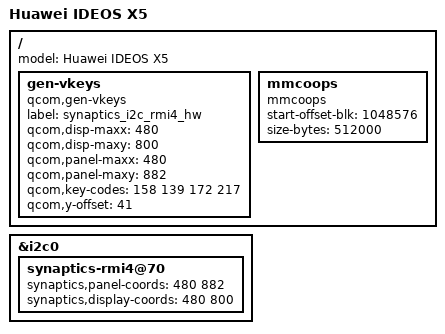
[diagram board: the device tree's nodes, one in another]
#include "qcom-msm7x30-huawei.dtsi"

/ {
	model = "Huawei IDEOS X5";

	gen-vkeys {
		compatible = "qcom,gen-vkeys";
		label = "synaptics_i2c_rmi4_hw";
		qcom,disp-maxx = <480>;
		qcom,disp-maxy = <800>;
		qcom,panel-maxx = <480>;
		qcom,panel-maxy = <882>;
		qcom,key-codes = <158 139 172 217>;
		qcom,y-offset = <41>;
	};

	mmcoops {
		compatible = "mmcoops";
		start-offset-blk = <1048576>; /* mmcblk0p7 */
		size-bytes = <512000>; /* 500 KiB */
	};
};

#include "mddi-panel-novatek-truly-type1.dtsi"

&i2c0 {
	synaptics-rmi4@70 {
		synaptics,panel-coords = <480 882>;
		synaptics,display-coords = <480 800>;
	};
};
